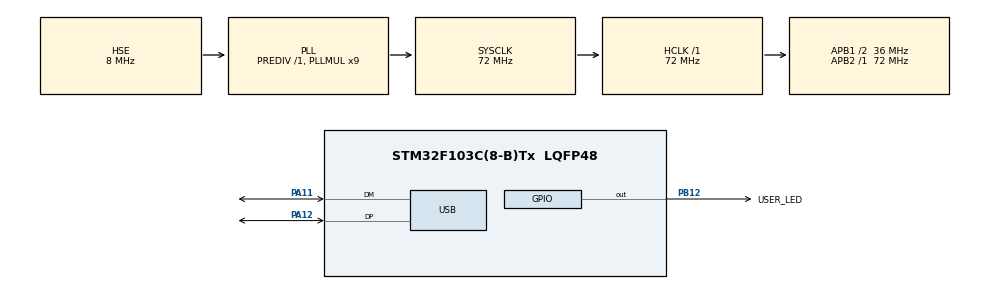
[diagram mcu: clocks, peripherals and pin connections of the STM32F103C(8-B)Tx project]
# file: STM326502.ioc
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FREERTOS.Tasks01=defaultTask,24,128,StartDefaultTask,Default,NULL,Dynamic,NULL,NULL
Mcu.Family=STM32F1
Mcu.Name=STM32F103C(8-B)Tx
Mcu.Package=LQFP48
NVIC.PriorityGroup=NVIC_PRIORITYGROUP_4
NVIC.TIM4_IRQn=true\:0\:0\:false\:false\:true\:false\:false\:true
NVIC.TimeBase=TIM4_IRQn
NVIC.TimeBaseIP=TIM4
NVIC.USB_HP_CAN1_TX_IRQn=true\:5\:0\:false\:false\:true\:true\:true\:true
NVIC.USB_LP_CAN1_RX0_IRQn=true\:5\:0\:false\:false\:true\:true\:true\:true
PA11.Mode=Device
PA11.Signal=USB_DM
PA12.Mode=Device
PA12.Signal=USB_DP
PA13.Mode=Serial_Wire
PA13.Signal=SYS_JTMS-SWDIO
PA14.Mode=Serial_Wire
PA14.Signal=SYS_JTCK-SWCLK
PB12.GPIO_Label=USER_LED
PB12.Signal=GPIO_Output
PD0-OSC_IN.Mode=HSE-External-Oscillator
PD0-OSC_IN.Signal=RCC_OSC_IN
PD1-OSC_OUT.Mode=HSE-External-Oscillator
PD1-OSC_OUT.Signal=RCC_OSC_OUT
ProjectManager.HeapSize=0x200
ProjectManager.StackSize=0x400
ProjectManager.TargetToolchain=Makefile
RCC.AHBFreq_Value=72000000
RCC.APB1CLKDivider=RCC_HCLK_DIV2
RCC.APB1Freq_Value=36000000
RCC.APB1TimFreq_Value=72000000
RCC.APB2Freq_Value=72000000
RCC.APB2TimFreq_Value=72000000
RCC.HCLKFreq_Value=72000000
RCC.PLLMUL=RCC_PLL_MUL9
RCC.SYSCLKFreq_VALUE=72000000
RCC.SYSCLKSource=RCC_SYSCLKSOURCE_PLLCLK
RCC.USBFreq_Value=48000000
RCC.USBPrescaler=RCC_USBCLKSOURCE_PLL_DIV1_5
USB_DEVICE.CLASS_NAME_FS=CDC
USB_DEVICE.VirtualMode=Cdc
USB_DEVICE.VirtualModeFS=Cdc_FS
VP_FREERTOS_VS_CMSIS_V2.Mode=CMSIS_V2
VP_SYS_VS_tim4.Mode=TIM4
VP_USB_DEVICE_VS_USB_DEVICE_CDC_FS.Mode=CDC_FS
board=custom

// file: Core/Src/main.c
/* USER CODE BEGIN Header */
/**
  ******************************************************************************
  * @file           : main.c
  * @brief          : Main program body
  ******************************************************************************
  * @attention
  *
  * <h2><center>&copy; Copyright (c) 2020 STMicroelectronics.
  * All rights reserved.</center></h2>
  *
  * This software component is licensed by ST under Ultimate Liberty license
  * SLA0044, the "License"; You may not use this file except in compliance with
  * the License. You may obtain a copy of the License at:
  *                             www.st.com/SLA0044
  *
  ******************************************************************************
  */
/* USER CODE END Header */

#include "main.h"
#include "cmsis_os.h"
#include "usb_device.h"

/* USER CODE BEGIN Includes */
#include "acia6850.h"
#include "fake6502.h"
#include "rom.h"
/* USER CODE END Includes */

osThreadId_t defaultTaskHandle;

void SystemClock_Config(void);
static void MX_GPIO_Init(void);
void StartDefaultTask(void *argument);

int main(void)
{

  /* MCU Configuration--------------------------------------------------------*/

  /* Reset of all peripherals, Initializes the Flash interface and the Systick. */
  HAL_Init();

  /* Configure the system clock */
  SystemClock_Config();

  /* Initialize all configured peripherals */
  MX_GPIO_Init();

  osKernelInitialize();

  /* Create the thread(s) */
  /* definition and creation of defaultTask */
  const osThreadAttr_t defaultTask_attributes = {
    .name = "defaultTask",
    .priority = (osPriority_t) osPriorityNormal,
    .stack_size = 128
  };
  defaultTaskHandle = osThreadNew(StartDefaultTask, NULL, &defaultTask_attributes);

  /* Start scheduler */
  osKernelStart();

  /* We should never get here as control is now taken by the scheduler */

  /* Infinite loop */
  while (1)
  {

  }
}

void SystemClock_Config(void)
{
  RCC_OscInitTypeDef RCC_OscInitStruct = {0};
  RCC_ClkInitTypeDef RCC_ClkInitStruct = {0};
  RCC_PeriphCLKInitTypeDef PeriphClkInit = {0};

  /** Initializes the CPU, AHB and APB busses clocks
  */
  RCC_OscInitStruct.OscillatorType = RCC_OSCILLATORTYPE_HSE;
  RCC_OscInitStruct.HSEState = RCC_HSE_ON;
  RCC_OscInitStruct.HSEPredivValue = RCC_HSE_PREDIV_DIV1;
  RCC_OscInitStruct.HSIState = RCC_HSI_ON;
  RCC_OscInitStruct.PLL.PLLState = RCC_PLL_ON;
  RCC_OscInitStruct.PLL.PLLSource = RCC_PLLSOURCE_HSE;
  RCC_OscInitStruct.PLL.PLLMUL = RCC_PLL_MUL9;
  if (HAL_RCC_OscConfig(&RCC_OscInitStruct) != HAL_OK)
  {
    Error_Handler();
  }
  /** Initializes the CPU, AHB and APB busses clocks
  */
  RCC_ClkInitStruct.ClockType = RCC_CLOCKTYPE_HCLK|RCC_CLOCKTYPE_SYSCLK
                              |RCC_CLOCKTYPE_PCLK1|RCC_CLOCKTYPE_PCLK2;
  RCC_ClkInitStruct.SYSCLKSource = RCC_SYSCLKSOURCE_PLLCLK;
  RCC_ClkInitStruct.AHBCLKDivider = RCC_SYSCLK_DIV1;
  RCC_ClkInitStruct.APB1CLKDivider = RCC_HCLK_DIV2;
  RCC_ClkInitStruct.APB2CLKDivider = RCC_HCLK_DIV1;

  if (HAL_RCC_ClockConfig(&RCC_ClkInitStruct, FLASH_LATENCY_2) != HAL_OK)
  {
    Error_Handler();
  }
  PeriphClkInit.PeriphClockSelection = RCC_PERIPHCLK_USB;
  PeriphClkInit.UsbClockSelection = RCC_USBCLKSOURCE_PLL_DIV1_5;
  if (HAL_RCCEx_PeriphCLKConfig(&PeriphClkInit) != HAL_OK)
  {
    Error_Handler();
  }
}

static void MX_GPIO_Init(void)
{
  GPIO_InitTypeDef GPIO_InitStruct = {0};

  /* GPIO Ports Clock Enable */
  __HAL_RCC_GPIOD_CLK_ENABLE();
  __HAL_RCC_GPIOB_CLK_ENABLE();
  __HAL_RCC_GPIOA_CLK_ENABLE();

  /*Configure GPIO pin Output Level */
  HAL_GPIO_WritePin( USER_LED_GPIO_Port, USER_LED_Pin, GPIO_PIN_RESET );

  /*Configure GPIO pin : USER_LED_Pin */
  GPIO_InitStruct.Pin = USER_LED_Pin;
  GPIO_InitStruct.Mode = GPIO_MODE_OUTPUT_PP;
  GPIO_InitStruct.Pull = GPIO_NOPULL;
  GPIO_InitStruct.Speed = GPIO_SPEED_FREQ_LOW;
  HAL_GPIO_Init( USER_LED_GPIO_Port, &GPIO_InitStruct );

  HAL_GPIO_WritePin( GPIOA, GPIO_PIN_11 | GPIO_PIN_12, GPIO_PIN_RESET );

  GPIO_InitStruct.Pin = GPIO_PIN_11 | GPIO_PIN_12;
  GPIO_InitStruct.Mode = GPIO_MODE_OUTPUT_PP;
  GPIO_InitStruct.Pull = GPIO_PULLDOWN;
  HAL_GPIO_Init( GPIOA, &GPIO_InitStruct );

}

/* USER CODE BEGIN 4 */
// 6502 processor memory, 10KB (< 20KB)
uint8_t ram[ 0x2D00U ];
uint8_t read6502(uint16_t address) {
	// RAM
	if (address < sizeof(ram)) {
		return ram[address];
	}

	// ROM
	if (address >= 0xc000) {
		const uint8_t *rom = &rom6502_start;

		return rom[address - 0xc000];
	}

	// ACIA
	if (address >= 0xa000 && address <= 0xbfff) {
		return read6850(address);
	}

	return 0xff;
}

void write6502(uint16_t address, uint8_t value) {
	// RAM
	if (address < sizeof(ram)) {
		ram[address] = value;
	}

	// ACIA
	if (address >= 0xa000 && address <= 0xbfff) {
		write6850(address, value);
	}

}
/* USER CODE END 4 */

void StartDefaultTask(void *argument)
{

	/* USER CODE BEGIN 5 */
	osDelay( 50U );
	/* init code for USB_DEVICE */
	MX_USB_DEVICE_Init();
	/* Infinite loop */
	for(;;)
	{
		step6502();
		//osDelay(1);
	}
	/* USER CODE END 5 */
}

void HAL_TIM_PeriodElapsedCallback(TIM_HandleTypeDef *htim)
{
  if (htim->Instance == TIM4) {
    HAL_IncTick();
  }
}

void Error_Handler(void)
{
}

/************************ (C) COPYRIGHT STMicroelectronics *****END OF FILE****/
